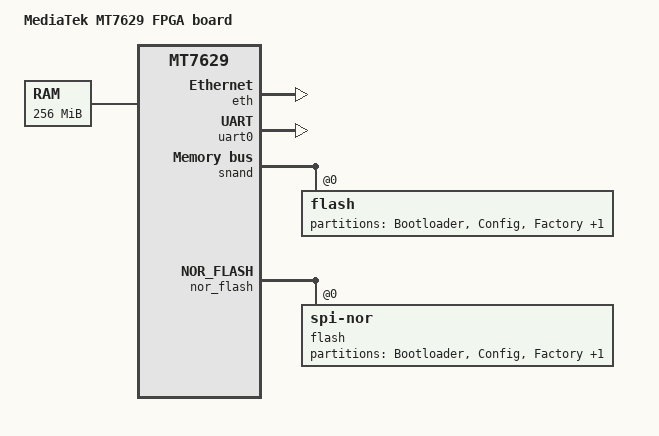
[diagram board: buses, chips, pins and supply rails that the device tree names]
/*
 * Copyright (c) 2017 MediaTek Inc.
 * Author: Dehui.Sun <dehui.sun@mediatek.com>
 *
 * This program is free software; you can redistribute it and/or modify
 * it under the terms of the GNU General Public License version 2 as
 * published by the Free Software Foundation.
 *
 * This program is distributed in the hope that it will be useful,
 * but WITHOUT ANY WARRANTY; without even the implied warranty of
 * MERCHANTABILITY or FITNESS FOR A PARTICULAR PURPOSE.  See the
 * GNU General Public License for more details.
 */

/dts-v1/;
#include "mt7629-fpga.dtsi"

/ {
	model = "MediaTek MT7629 FPGA board";
	compatible = "mediatek,mt7629-fpga", "mediatek,mt7629";

	chosen {
		bootargs = "earlycon=uart8250,mmio32,0x11002000 console=ttyS0,115200n1 \
loglevel=8 failsafe=true";
	};

	memory {
		device_type = "memory";
		reg = <0 0x40000000 0 0x10000000>;
	};
};

&eth {
	mac-address = [00 00 00 00 00 00];
	gmac1-support = "none";
	gmac2-support = "rgmii-2";
	rgmii-mode-2 = "an";
	gmac2-phy-address = <0>;
	gmac1_txq_num = <1>;
	gmac1_txq_txd_num = <2048>;
	gmac2_txq_num = <1>;
	gmac2_txq_txd_num = <1024>;
	num_rx_desc = <2048>;
	status = "okay";
};

&uart0 {
	status = "okay";
};

&snand {
	status = "okay";
	flash@0 {
		partitions {
			compatible = "fixed-partitions";
			#address-cells = <1>;
			#size-cells = <1>;

			partition@0 {
				label = "Bootloader";
				reg = <0x00000 0x0100000>;
				read-only;
			};

			partition@100000 {
				label = "Config";
				reg = <0x100000 0x0040000>;
			};

			partition@140000 {
				label = "Factory";
				reg = <0x140000 0x0080000>;
			};

			partition@1c0000 {
				label = "Kernel";
				reg = <0x1c0000 0x2000000>;
			};
		};
	};
};

&nor_flash {
	status = "okay";
	flash@0 {
		compatible = "jedec,spi-nor";
		#address-cells = <1>;
		#size-cells = <1>;
		partition@00000 {
			label = "Bootloader";
			reg = <0x00000 0x0060000>;
		};
		partition@60000 {
			label = "Config";
			reg = <0x60000 0x0010000>;
		};
		partition@70000 {
			label = "Factory";
			reg = <0x70000 0x0040000>;
		};
		partition@b0000 {
			label = "Kernel";
			reg = <0xb0000 0x720000>;
		};
	};
};

